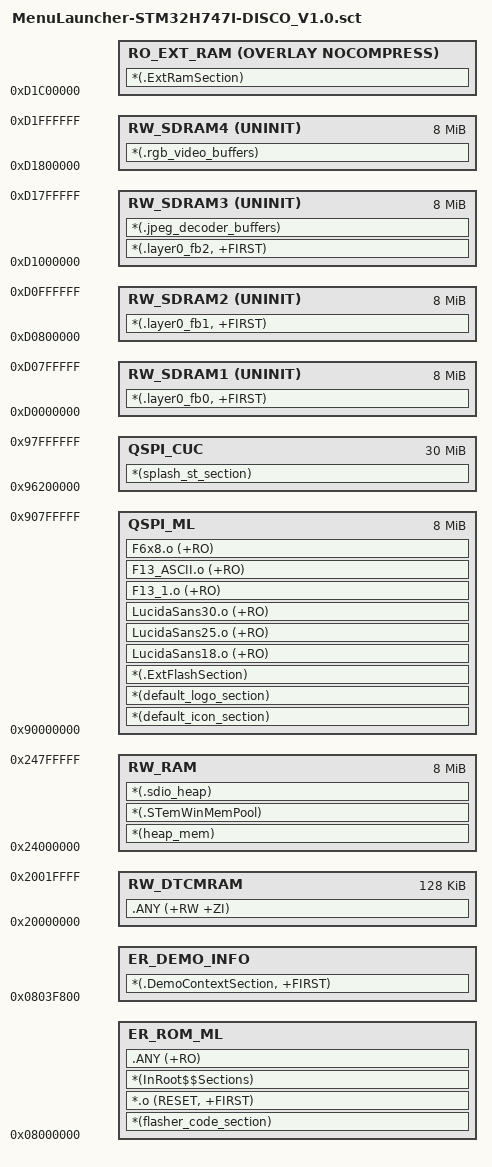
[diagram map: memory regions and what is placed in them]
; *************************************************************
; *** Scatter-Loading Description File generated by uVision ***
; *************************************************************

LR_ROM_ML 0x08000000 0x3F800 {    ; load region size_region
	ER_ROM_ML 0x08000000  {  ; load address = execution address
		*(flasher_code_section)
		*.o (RESET, +FIRST)
		*(InRoot$$Sections)
		.ANY (+RO)
}
	RW_DTCMRAM 0x20000000 0x00020000  {  ; RW data
		.ANY (+RW +ZI)
}
	RW_RAM  0x24000000 0x800000  {  ; RW data
		*(heap_mem)
		*(.STemWinMemPool)
		*(.sdio_heap)
}
}

LR_DEMO_INFO 0x0803F800 0x800  {
	ER_DEMO_INFO 0x0803F800 {
		*(.DemoContextSection, +FIRST)
}
}

LR_SDRAM 0xD0000000  {
	RW_SDRAM1 0xD0000000 UNINIT 0x800000 {  ; RW data
		*(.layer0_fb0, +FIRST)
}
	RW_SDRAM2 0xD0800000 UNINIT 0x800000 {  ; RW data
		*(.layer0_fb1, +FIRST)
}
	RW_SDRAM3 0xD1000000 UNINIT 0x800000 {  ; RW data
		*(.layer0_fb2, +FIRST)
		*(.jpeg_decoder_buffers)
}
	RW_SDRAM4 0xD1800000 UNINIT 0x800000 {  ; RW data
		*(.rgb_video_buffers)
}
}

LR_QSPI_ML 0x90000000 {

	QSPI_ML  0x90000000 0x800000  {  
		*(default_icon_section)
		*(default_logo_section)
		*(.ExtFlashSection)
		LucidaSans18.o (+RO)
		LucidaSans25.o (+RO)
		LucidaSans30.o (+RO)
		F13_1.o  (+RO)
		F13_ASCII.o (+RO)
		F6x8.o  (+RO)
}
}

LR_QSPI_CUC 0x96200000 {
	QSPI_CUC  0x96200000 0x1E00000  {  ; RW data
		*(splash_st_section)
}
	RO_EXT_RAM 0xD1800000+0x400000 OVERLAY NOCOMPRESS {
		*(.ExtRamSection)
}
}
